# STC32G144K246 register map
Vendor: STC; File version: 2.0
Registers are 8-bit, read-write, no defined reset value unless marked. A register's access mark holds for its fields unless they carry their own. Offsets are from the block's base; [hi:lo] are bit positions; {n}, {i} and the like mark numbered series.

## Watchdog — 看门狗
Base 0x100000C1
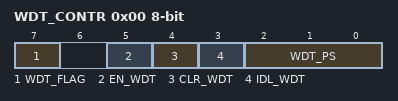
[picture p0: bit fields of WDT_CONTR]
0x00 WDT_CONTR ro — 看门狗控制寄存器
  [7] WDT_FLAG — 看门狗溢出标志 看门狗发生溢出时，硬件自动将此位置1，需要软件清零。
  [5] EN_WDT — 看门狗使能位
    0=对单片机无影响; 1=启动看门狗定时器
  [4] CLR_WDT — 看门狗定时器清零
    0=对单片机无影响; 1=清零看门狗定时器，硬件自动将此位复位
  [3] IDL_WDT — IDLE 模式时的看门狗控制位
    0=IDLE 模式时看门狗停止计数; 1=IDLE 模式时看门狗继续计数
  [2:0] WDT_PS — 看门狗定时器时钟分频系数
    0=分频系数：2；12M 主频时的溢出时间：≈ 65.5 毫秒；20M 主频时的溢出时间：≈ 39.3 毫秒; 1=分频系数：4；12M 主频时的溢出时间：≈ 131 毫秒；20M 主频时的溢出时间：≈ 78.6 毫秒; 2=分频系数：8；12M 主频时的溢出时间：≈ 262 毫秒；20M 主频时的溢出时间：≈ 157 毫秒; 3=分频系数：16；12M 主频时的溢出时间：≈ 524 毫秒；20M 主频时的溢出时间：≈ 315 毫秒; 4=分频系数：32；12M 主频时的溢出时间：≈ 1.05 秒；20M 主频时的溢出时间：≈ 629 毫秒; 5=分频系数：64；12M 主频时的溢出时间：≈ 2.10 秒；20M 主频时的溢出时间：≈ 1.26 秒; 6=分频系数：128；12M 主频时的溢出时间：≈ 4.20 秒；20M 主频时的溢出时间：≈ 2.52 秒; 7=分频系数：256；12M 主频时的溢出时间：≈ 8.39 秒；20M 主频时的溢出时间：≈ 5.03 秒

## WakeTimer — 掉电唤醒定时器
Base 0x100000AA
0x00 WKTCL — 掉电唤醒定时器低字节
  [7:0] WKTC — 尚未自动匹配到此字段的独立说明；请查看下方章节说明。
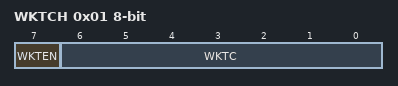
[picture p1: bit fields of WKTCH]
0x01 WKTCH — 掉电唤醒定时器高字节
  [7] WKTEN — 掉电唤醒定时器的使能控制位
    0=停用掉电唤醒定时器; 1=启用掉电唤醒定时器
  [6:0] WKTC — 尚未自动匹配到此字段的独立说明；请查看下方章节说明。

## MemoryBus — Flash 等待周期、片内 RAM 总线与缓存相关控制
Base 0x100000A1
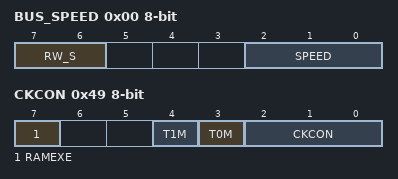
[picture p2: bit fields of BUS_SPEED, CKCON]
0x00 BUS_SPEED ro — 总线速度控制寄存器
  [7:6] RW_S — RD/WR 控制线选择位
  [2:0] SPEED — 总线读写速度控制（读写数据时控制信号和数据信号的准备时间和保持时间）
0x48 WTST ro — 程序读取等待控制寄存器
  [7:0] WTST — 高速i-Cache 读取慢速Flash 程序存储器的等待时时钟设置
0x49 CKCON ro — XRAM控制寄存器
  [7] RAMEXE — 80:0000H ~ 80:0FFFH 区域4K 可执行RAM 控制位
    0=此区域为数据区域，可读、可写、不可运行代码; 1=此区域为程序区域，可读、可运行代码、不可写
  [4] T1M — 保留
  [3] T0M — 保留
  [2:0] CKCON — 外部数据总线时钟控制寄存器（上电复位值为7，强烈建议上电初始化为0）

## GPIO0 — P0 端口、模式、上下拉和中断
Base 0x007EFD00
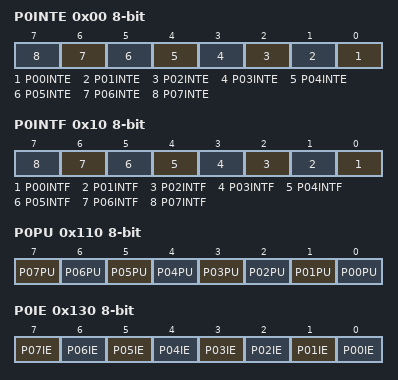
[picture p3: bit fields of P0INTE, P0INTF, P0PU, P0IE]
0x00 P0INTE — P0口中断使能寄存器
  [n] P{n:02}INTE (n=0..7) — 尚未自动匹配到此字段的独立说明；请查看下方章节说明。
0x10 P0INTF ro — P0口中断标志寄存器
  [n] P{n:02}INTF (n=0..7) — 尚未自动匹配到此字段的独立说明；请查看下方章节说明。
0x110 P0PU — P0口上拉电阻控制寄存器
  [all] fields
    0=禁止内部上拉电阻; 1=使能内部上拉电阻
  [7] P07PU — 控制 P0.7 的内部上拉电阻。
  [6] P06PU — 控制 P0.6 的内部上拉电阻。
  [5] P05PU — 控制 P0.5 的内部上拉电阻。
  [4] P04PU — 控制 P0.4 的内部上拉电阻。
  [3] P03PU — 控制 P0.3 的内部上拉电阻。
  [2] P02PU — 控制 P0.2 的内部上拉电阻。
  [1] P01PU — 控制 P0.1 的内部上拉电阻。
  [0] P00PU — 控制 P0.0 的内部上拉电阻。
0x130 P0IE — P0口输入使能控制寄存器
  [all] fields
    0=禁止数字信号输入，用于模拟功能; 1=使能数字信号输入
  [7] P07IE — 控制 P0.7 的数字信号输入。
  [6] P06IE — 控制 P0.6 的数字信号输入。
  [5] P05IE — 控制 P0.5 的数字信号输入。
  [4] P04IE — 控制 P0.4 的数字信号输入。
  [3] P03IE — 控制 P0.3 的数字信号输入。
  [2] P02IE — 控制 P0.2 的数字信号输入。
  [1] P01IE — 控制 P0.1 的数字信号输入。
  [0] P00IE — 控制 P0.0 的数字信号输入。
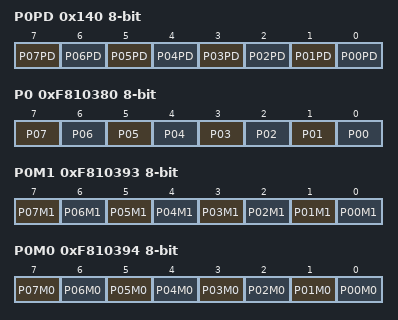
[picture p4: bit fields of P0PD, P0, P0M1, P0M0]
0x140 P0PD — P0口下拉电阻控制寄存器
  [all] fields
    0=禁止内部下拉电阻; 1=使能内部下拉电阻
  [7] P07PD — 控制 P0.7 的内部下拉电阻。
  [6] P06PD — 控制 P0.6 的内部下拉电阻。
  [5] P05PD — 控制 P0.5 的内部下拉电阻。
  [4] P04PD — 控制 P0.4 的内部下拉电阻。
  [3] P03PD — 控制 P0.3 的内部下拉电阻。
  [2] P02PD — 控制 P0.2 的内部下拉电阻。
  [1] P01PD — 控制 P0.1 的内部下拉电阻。
  [0] P00PD — 控制 P0.0 的内部下拉电阻。
0xF810380 P0 — P0端口
  [all] fields
    0=低电平; 1=高电平
  [7] P07 — 读取 P0.7 管脚电平；写入 P0.7 的输出缓冲区。实际输出行为由端口模式及外设复用共同决定。
  [6] P06 — 读取 P0.6 管脚电平；写入 P0.6 的输出缓冲区。实际输出行为由端口模式及外设复用共同决定。
  [5] P05 — 读取 P0.5 管脚电平；写入 P0.5 的输出缓冲区。实际输出行为由端口模式及外设复用共同决定。
  [4] P04 — 读取 P0.4 管脚电平；写入 P0.4 的输出缓冲区。实际输出行为由端口模式及外设复用共同决定。
  [3] P03 — 读取 P0.3 管脚电平；写入 P0.3 的输出缓冲区。实际输出行为由端口模式及外设复用共同决定。
  [2] P02 — 读取 P0.2 管脚电平；写入 P0.2 的输出缓冲区。实际输出行为由端口模式及外设复用共同决定。
  [1] P01 — 读取 P0.1 管脚电平；写入 P0.1 的输出缓冲区。实际输出行为由端口模式及外设复用共同决定。
  [0] P00 — 读取 P0.0 管脚电平；写入 P0.0 的输出缓冲区。实际输出行为由端口模式及外设复用共同决定。
0xF810393 P0M1 — P0口配置寄存器1
  [7] P07M1 — 控制 P0.7 的端口模式高位；与 P0M0.B7 配合设置，组合含义见下表。
  [6] P06M1 — 控制 P0.6 的端口模式高位；与 P0M0.B6 配合设置，组合含义见下表。
  [5] P05M1 — 控制 P0.5 的端口模式高位；与 P0M0.B5 配合设置，组合含义见下表。
  [4] P04M1 — 控制 P0.4 的端口模式高位；与 P0M0.B4 配合设置，组合含义见下表。
  [3] P03M1 — 控制 P0.3 的端口模式高位；与 P0M0.B3 配合设置，组合含义见下表。
  [2] P02M1 — 控制 P0.2 的端口模式高位；与 P0M0.B2 配合设置，组合含义见下表。
  [1] P01M1 — 控制 P0.1 的端口模式高位；与 P0M0.B1 配合设置，组合含义见下表。
  [0] P00M1 — 控制 P0.0 的端口模式高位；与 P0M0.B0 配合设置，组合含义见下表。
0xF810394 P0M0 — P0口配置寄存器0
  [7] P07M0 — 控制 P0.7 的端口模式低位；与 P0M1.B7 配合设置，组合含义见下表。
  [6] P06M0 — 控制 P0.6 的端口模式低位；与 P0M1.B6 配合设置，组合含义见下表。
  [5] P05M0 — 控制 P0.5 的端口模式低位；与 P0M1.B5 配合设置，组合含义见下表。
  [4] P04M0 — 控制 P0.4 的端口模式低位；与 P0M1.B4 配合设置，组合含义见下表。
  [3] P03M0 — 控制 P0.3 的端口模式低位；与 P0M1.B3 配合设置，组合含义见下表。
  [2] P02M0 — 控制 P0.2 的端口模式低位；与 P0M1.B2 配合设置，组合含义见下表。
  [1] P01M0 — 控制 P0.1 的端口模式低位；与 P0M1.B1 配合设置，组合含义见下表。
  [0] P00M0 — 控制 P0.0 的端口模式低位；与 P0M1.B0 配合设置，组合含义见下表。
